# EDM register map
Vendor: Texas Instruments
Peripheral module from a debugger description file (folder omap5430_ES2_PUBLIC).
Registers are 32-bit, access per field, reset 0x0 unless marked. A register's access mark holds for its fields unless they carry their own. Offsets are as the file gives them; lines under a group give offsets from that group; [hi:lo] are bit positions; {n}, {i} and the like mark numbered series; 'fields as' and 'values as' point back to an identical list; <NAME> marks a mode.

## EDM
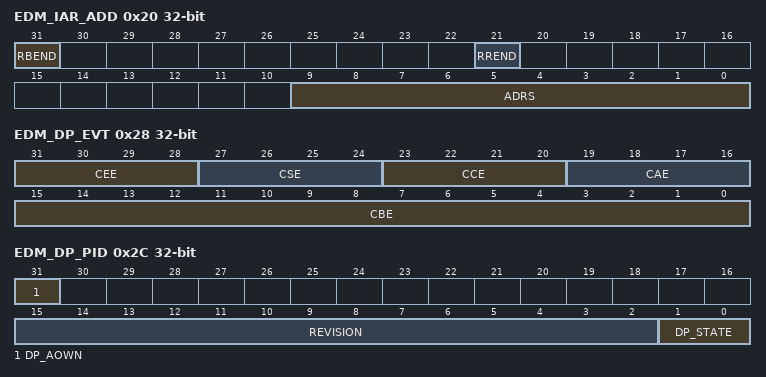
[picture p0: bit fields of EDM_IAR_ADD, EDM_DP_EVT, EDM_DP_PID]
0x20 EDM_IAR_ADD — Indirect Register Acces
  [31] RBEND rw — A one results the Breakpoint End(BEND) status. A zero causes no action.
  [21] RREND rw — A one resets the RTOSS Int (AINT) End (RREND) status. A zero causes no action
  [9:0] ADRS rw — This 10-bit value creates the indirect register address.
0x24 EDM_IAR_DAT rw
  [31:0] DATA — Read: Indirectly Addressable Register Read Data. Write: Indirectly Addressable Register Write Data.
0x28 EDM_DP_EVT rw
  [31:28] CEE — Reserved for Extra Events
  [27:24] CSE — State Events
  [23:20] CCE — Counter Events
  [19:16] CAE — Auxiliary Events
  [15:0] CBE — Bus Events
0x2C EDM_DP_PID (reset mask 0xFFFF0003)
  [31] DP_AOWN rw — Ownership
    0=Debug_owned; 1=Application_owned
  [15:2] REVISION ro — Revision ID
  [1:0] DP_STATE rw — State
    0=AVAIL_state; 1=APP_CLAIMor_DBG_CLAIM; 2=APP_ENA_or_DBG_ENA
0x30 EDM_DP_PC ro
  [31:0] CPC — Current CPU PC
